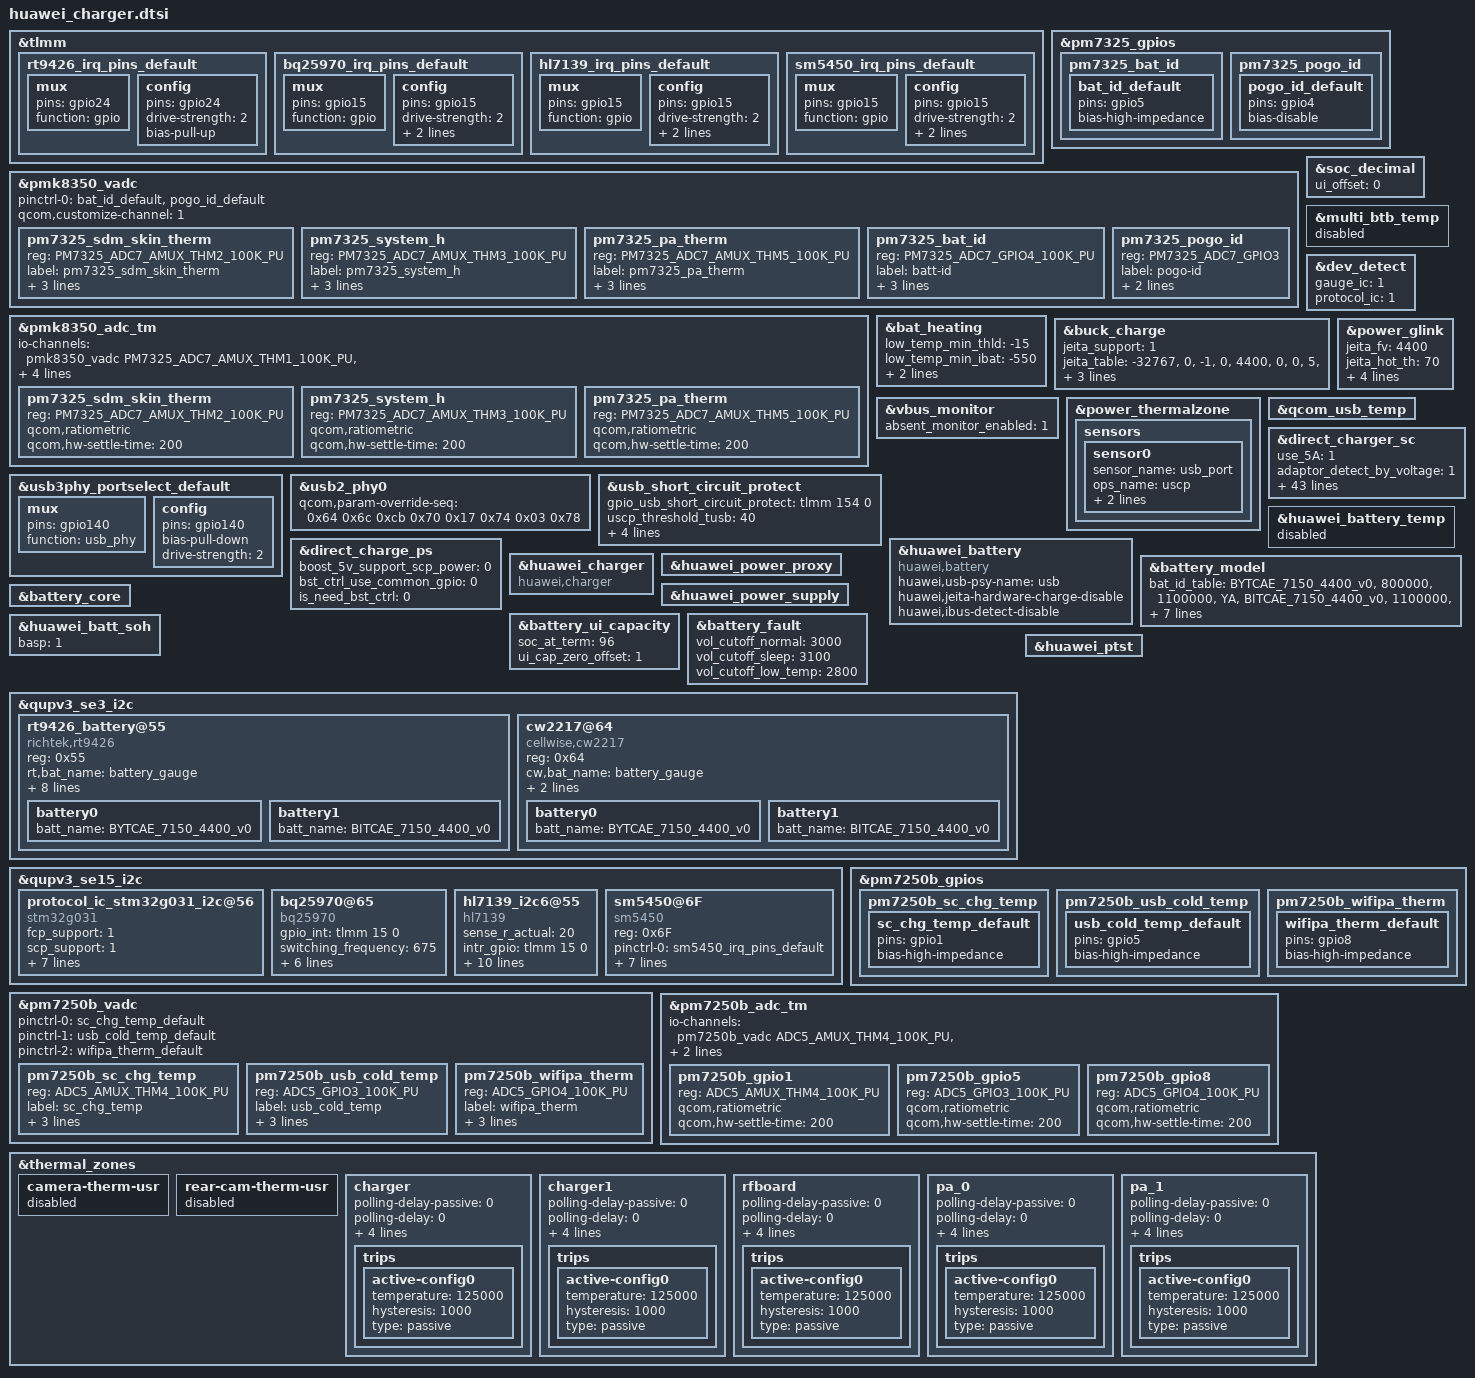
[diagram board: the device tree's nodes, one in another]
#include <dt-bindings/iio/qcom,spmi-vadc.h>

&tlmm {
	rt9426_irq_pins_default: rt9426_irq_pins_default {
		mux {
			pins = "gpio24";
			function = "gpio";
		};
		config {
			pins = "gpio24";
			drive-strength = <2>;
			bias-pull-up;
		};
	};

	bq25970_irq_pins_default: bq25970_irq_pins_default {
		mux {
			pins = "gpio15";
			function = "gpio";
		};
		config {
			pins = "gpio15";
			drive-strength = <2>;
			bias-pull-up;
			input-enable;
		};
	};

	hl7139_irq_pins_default: hl7139_irq_pins_default {
		mux {
			pins = "gpio15";
			function = "gpio";
		};
		config {
			pins = "gpio15";
			drive-strength = <2>;
			bias-pull-up;
			input-enable;
		};
	};

	sm5450_irq_pins_default: sm5450_irq_pins_default {
		mux {
			pins = "gpio15";
			function = "gpio";
		};
		config {
			pins = "gpio15";
			drive-strength = <2>;
			bias-pull-up;
			input-enable;
		};
	};
};

&pm7325_gpios {
	pm7325_bat_id {
		bat_id_default: bat_id_default {
		pins = "gpio5";
		bias-high-impedance;
		};
	};

	pm7325_pogo_id {
		pogo_id_default: pogo_id_default {
			pins = "gpio4";
			bias-disable;
		};
	};
};

&pmk8350_vadc {
	pinctrl-names = "default";
	pinctrl-0 = < &bat_id_default &pogo_id_default>;
	qcom,customize-channel = <1>;

	/delete-node/ pm7325_cam_flash_therm;
	/delete-node/ pm7325_wide_rfc_therm;

	pm7325_sdm_skin_therm {
		reg = <PM7325_ADC7_AMUX_THM2_100K_PU>;
		label = "pm7325_sdm_skin_therm";
		qcom,ratiometric;
		qcom,hw-settle-time = <200>;
		qcom,pre-scaling = <1 1>;
	};

	pm7325_system_h {
		reg = <PM7325_ADC7_AMUX_THM3_100K_PU>;
		label = "pm7325_system_h";
		qcom,ratiometric;
		qcom,hw-settle-time = <200>;
		qcom,pre-scaling = <1 1>;
	};

	pm7325_pa_therm {
		reg = <PM7325_ADC7_AMUX_THM5_100K_PU>;
		label = "pm7325_pa_therm";
		qcom,ratiometric;
		qcom,hw-settle-time = <200>;
		qcom,pre-scaling = <1 1>;
	};

	pm7325_bat_id {
		reg = < PM7325_ADC7_GPIO4_100K_PU>;
		label = "batt-id";
		qcom,ratiometric;
		qcom,hw-settle-time = <200>;
		qcom,pre-scaling = <1 1>;
	};

	pm7325_pogo_id {
		reg = <PM7325_ADC7_GPIO3>;
		label = "pogo-id";
		qcom,hw-settle-time = <200>;
		qcom,pre-scaling = <1 1>;
	};
};


&pmk8350_adc_tm {
	io-channels = <&pmk8350_vadc PM7325_ADC7_AMUX_THM1_100K_PU>,
			<&pmk8350_vadc PM7325_ADC7_AMUX_THM2_100K_PU>,
			<&pmk8350_vadc PM7325_ADC7_AMUX_THM3_100K_PU>,
			<&pmk8350_vadc PM7325_ADC7_AMUX_THM5_100K_PU>,
			<&pmk8350_vadc PMK8350_ADC7_AMUX_THM1_100K_PU>;

	/delete-node/ pm7325_cam_flash_therm;
	/delete-node/ pm7325_wide_rfc_therm;

	pm7325_sdm_skin_therm {
		reg = <PM7325_ADC7_AMUX_THM2_100K_PU>;
		qcom,ratiometric;
		qcom,hw-settle-time = <200>;
	};

	pm7325_system_h {
		reg = <PM7325_ADC7_AMUX_THM3_100K_PU>;
		qcom,ratiometric;
		qcom,hw-settle-time = <200>;
	};

	pm7325_pa_therm {
		reg = <PM7325_ADC7_AMUX_THM5_100K_PU>;
		qcom,ratiometric;
		qcom,hw-settle-time = <200>;
	};
};

&bat_heating {
	low_temp_min_thld = "-15";
	low_temp_min_ibat = "-550";
	temp_para =
		"-32767", "0", "0",
		"0", "5", "0",
		"5", "10", "400",
		"10", "20", "2500",
		"20", "45", "4500",
		"45", "32767", "0";
	status = "ok";
};

&soc_decimal {
	ui_offset = <0>;
	status = "ok";
};

&multi_btb_temp {
	status = "disabled";
};

&dev_detect {
        gauge_ic = <1>;
        protocol_ic = <1>;
        status = "ok";
};

&buck_charge {
	jeita_support = <1>;
	jeita_table =
		"-32767", "0", "-1", "0", "4400", "0",
		"0", "5", "-1", "715", "4400", "0",
		"5", "10", "-1", "2145", "4400", "3",
		"10", "45", "-1", "3000", "4400", "3",
		"45", "50", "-1", "2502", "4100", "3",
		"50", "32767", "-1", "0", "4100", "0";
	status = "ok";
};

&power_glink {
	jeita_fv = <4400>;
	jeita_hot_th = <70>;
	fcp_pd_support_icl = <1>;
	iterm = <200>;
	adsp_jeita_table = <
		0 5 3000 4400
		5 10 3000 4400
		10 65 3000 4400
		65 70 3000 4400
	>;
};

&vbus_monitor {
	status = "ok";
	absent_monitor_enabled = <1>;
};

&power_thermalzone {
	status = "ok";
	sensors{
		sensor0 {
			sensor_name = "usb_port";
			ops_name = "uscp";
			adc_channel = <0>;
			ntc_index = <5>;
		};
	};
};

&qcom_usb_temp {
	status = "ok";
};

&usb3phy_portselect_default {
	mux {
		pins = "gpio140";
		function = "usb_phy";
	};

	config {
		pins = "gpio140";
		bias-pull-down;
		drive-strength = <2>;
	};
};

&usb2_phy0 {
	status = "ok";
			qcom,param-override-seq =
				<0x64 0x6c  /* override_x0 */
				0xcb 0x70  /* override_x1 */
				0x17 0x74  /* override_x2 */
				0x03 0x78>;    /* override_x3 */
};

&usb_short_circuit_protect {
	gpio_usb_short_circuit_protect = <&tlmm 154 0>; /* GPIO_154 */
	uscp_threshold_tusb = <40>;
	open_mosfet_temp = <30>;
	close_mosfet_temp = <10>;
	open_hiz_temp = <30>;
	interval_switch_temp = <15>;
	status = "ok";
};

&direct_charge_ps {
	boost_5v_support_scp_power = <0>;
	bst_ctrl_use_common_gpio = <0>;
	is_need_bst_ctrl = <0>;
	status = "ok";
};

&direct_charger_sc {
	use_5A = <1>;
	adaptor_detect_by_voltage = <1>;
	adaptor_antifake_check_enable = <0>;
	adaptor_antifake_key_index = <2>;
	need_wired_sw_off = <0>;
	dc_volt_ratio = <2>;
	max_adaptor_vset = <10000>;
	init_adapter_vset = <8800>;
	delta_err_10v2p25a = <150>;
	vol_err_th = <500>;
	adaptor_leakage_current_th = <600>;
	high_temp_hysteresis = <1>;
	gain_curr_10v2a = <300>;
	gain_curr_10v2p25a = <500>;
	init_delt_vset = <450>;
	vstep = <20>;
	min_dc_bat_vol = <3450>;
	max_dc_bat_vol = <4380>;
	product_max_pwr = <66000>;
	max_current_for_none_standard_cable = <6000>;
	volt_para =
		"4300","5000","4900",
		"4400","5000","1200";
	volt_para1 =
		"4300","5000","4900",
		"4400","5000","1200";
	time_para =
		"1140", "6200",
		"960", "8200",
		"360", "9300";
	bat_para =
		"CAE", "10", "20", "volt_para",
		"CAE", "20", "45", "volt_para1",
		"default", "10", "20", "volt_para",
		"default", "20", "45", "volt_para1";
	vstep_para =
			"2000", "80";
	compensate_r = <0>;
	cc_cable_detect_enable = <1>;
	full_path_res_max = <500>;
	scp_work_on_charger = <1>;
	standard_cable_full_path_res_max = <500>;
	first_cc_stage_timer_in_min = <14>;
	stage_need_to_jump = "-1";
	is_show_ico_first = <1>;
	is_send_cable_type = <0>;
	support_multi_ic = <1>;
	rt_test_para =
		/* first:sc second:mainsc third:auxsc */
		"500", "105",
		"500", "105",
		"500", "105";
	temp_para =
		"-32767", "10", "0",
		"10", "45", "13000",
		"45", "32767", "0";
	resist_para =
		"0", "300", "6000",
		"300", "500", "5000";
	std_resist_para =
		"0", "300", "13000",
		"300", "500", "5000";
	10v2p25a_cur_para =
		"-32767", "5500",  "2000",
		"5500",   "9000",  "2500",
		"9000",   "10000", "2250",
		"10000",  "10500", "2000",
		"10500",  "32767", "1500";
	status = "ok";
};

&huawei_battery_temp {
	status = "disabled";
};

&huawei_battery {
	compatible = "huawei,battery";
	status = "ok";
	huawei,usb-psy-name = "usb";
	huawei,jeita-hardware-charge-disable;
	huawei,ibus-detect-disable;
};

&huawei_charger {
	compatible = "huawei,charger";
	status = "ok";
};

&battery_model {
	bat_id_table =
		"BYTCAE_7150_4400_v0", "800000", "1100000", "YA",
		"BITCAE_7150_4400_v0", "1100000", "1350000", "CA";
	design_fcc = <7150>;

	support_iio = <1>;
	io-channels = <&pmk8350_vadc PM7325_ADC7_GPIO4_100K_PU>;
	io-channel-names = "batt-id";

	id_adc_channel = <0>; /* useless but necessary for Qcom, set 0 as default */
	technology = <2>;
	status = "ok";
};

&huawei_power_proxy {
	status = "ok";
};

&huawei_power_supply {
	 status = "ok";
};

&battery_core {
	status = "ok";
};

&battery_ui_capacity {
	soc_at_term = <96>;
	ui_cap_zero_offset = <1>;
	status = "ok";
};

&battery_fault {
	vol_cutoff_normal = <3000>;
	vol_cutoff_sleep = <3100>;
	vol_cutoff_low_temp = <2800>;
	status = "ok";
};

&huawei_batt_soh {
	basp = <1>;
	status = "ok";
};

&qupv3_se3_i2c {
	#address-cells = <1>;
	#size-cells = <0>;
	status = "ok";
	rt9426_battery@55{
		reg = <0x55>;
		compatible = "richtek,rt9426";
		rt,bat_name = "battery_gauge";
		pinctrl-names = "default";
		pinctrl-0 = <&rt9426_irq_pins_default>;
		rt9426,gpio-intb = <&tlmm 24 0x0>;
		need_reset_version = <9>;
		rt_config_ver = <11>;
		ntc_compensation_is = <1>;
		ntc_temp_compensation_para =
			"17000", "170",
			"15000", "150",
			"13000", "130",
			"11000", "110",
			"9000", "80",
			"7000", "50",
			"6000", "40",
			"5000", "30",
			"3000", "20",
			"2000", "10";
		status = "ok";
		battery0{
			batt_name = "BYTCAE_7150_4400_v0";
			#include "../../../huawei_charger/rt9426_BYTCAE_4V4_7150mAh_BACH4.dtsi"
		};
		battery1{
			batt_name = "BITCAE_7150_4400_v0";
			#include "../../../huawei_charger/rt9426_BITCAE_4V4_7150mAh_BACH4.dtsi"
		};
	};

	cw2217@64 {
		compatible = "cellwise,cw2217";
		reg = <0x64>;
		cw,bat_name = "battery_gauge";
		ground_loop_comp_en = <1>;
		ground_loop_comp_rcomp = <125>;
		status = "ok";
		battery0{
			batt_name = "BYTCAE_7150_4400_v0";
			#include "../../../huawei_charger/cw2217_2mohm_BYTCAE_7150mAh_4V4_BACH4.dtsi"
		};
		battery1{
			batt_name = "BITCAE_7150_4400_v0";
			#include "../../../huawei_charger/cw2217_2mohm_BITCAE_7150mAh_4V4_BACH4.dtsi"
		};
	};
};

&qupv3_se15_i2c {
	#address-cells = <1>;
	#size-cells = <0>;
	status = "ok";

	protocol_ic_stm32g031_i2c@56 {
		compatible = "stm32g031";
		fcp_support = <1>;
		scp_support = <1>;
		ufcs_support = <1>;
		wait_time = <20>;
		hw_config = <0x20>;
		gpio_enable = <&tlmm 68 0>;
		gpio_reset = <&tlmm 33 0>;
		gpio_int = <&tlmm 16 0>;
		reg = <0x56>;
		status = "ok";
	};

	bq25970@65 {
		compatible = "bq25970";
		gpio_int = <&tlmm 15 0>;
		switching_frequency = <675>;
		reg = <0x65>;
		pinctrl-names = "default";
		pinctrl-0 = <&bq25970_irq_pins_default>;
		ic_role = <0>;
		sense_r_actual = <20>;
		resume_need_wait_i2c = <1>;
		reset_ac_ovp = <1>;
		status = "ok";
	};

	hl7139_i2c6@55 {
		compatible = "hl7139";
		pinctrl-names = "default";
		sense_r_actual = <20>;
		intr_gpio = <&tlmm 15 0>;
		pinctrl-0 = <&hl7139_irq_pins_default>;
		fcp_support = <1>;
		scp_support = <1>;
		switching_frequency = <675>;
		reg = <0x55>;
		vbat_ovp_para = <5000>;
		ibat_ocp_para = <6000>;
		vin_ovp_para = <11500>;
		iin_ocp_para = <3750>;
		sc_ibus_ocp = <3750>;
		status = "ok";
	};

	sm5450@6F {
		compatible = "sm5450";
		reg = <0x6F>;
		pinctrl-names = "default";
		pinctrl-0 = <&sm5450_irq_pins_default>;
		intr_gpio_num = <15>; /* direct defined GPIO num */
		intr_gpio = <&tlmm 15 0>;
		fcp_support = <1>;
		scp_support = <1>;
		sense_r_actual = <20>;
		close_regulation = <1>;
		sc_ibus_ocp = <5700>;
		status = "ok";
	};
};

&huawei_ptst {
	status = "ok";
};


&pm7250b_gpios {
	pm7250b_sc_chg_temp {
		sc_chg_temp_default: sc_chg_temp_default {
			pins = "gpio1";
			bias-high-impedance;
		};
	};

	pm7250b_usb_cold_temp {
		usb_cold_temp_default: usb_cold_temp_default {
			pins = "gpio5";
			bias-high-impedance;
		};
	};

	pm7250b_wifipa_therm {
		wifipa_therm_default: wifipa_therm_default {
			pins = "gpio8";
			bias-high-impedance;
		};
	};

};

&pm7250b_vadc {
	#address-cells = <1>;
	#size-cells = <0>;
	pinctrl-names = "default", "default", "default";
	pinctrl-0 = <&sc_chg_temp_default>;
	pinctrl-1 = <&usb_cold_temp_default>;
	pinctrl-2 = <&wifipa_therm_default>;

	pm7250b_sc_chg_temp {
		reg = <ADC5_AMUX_THM4_100K_PU>;
		label = "sc_chg_temp";
		qcom,ratiometric;
		qcom,hw-settle-time = <200>;
		qcom,pre-scaling = <1 1>;
	};

	pm7250b_usb_cold_temp {
		reg = <ADC5_GPIO3_100K_PU>;
		label = "usb_cold_temp";
		qcom,ratiometric;
		qcom,hw-settle-time = <200>;
		qcom,pre-scaling = <1 1>;
	};

	pm7250b_wifipa_therm {
		reg = <ADC5_GPIO4_100K_PU>;
		label = "wifipa_therm";
		qcom,ratiometric;
		qcom,hw-settle-time = <200>;
		qcom,pre-scaling = <1 1>;
	};
};

&pm7250b_adc_tm {
	#address-cells = <1>;
	#size-cells = <0>;
	io-channels = <&pm7250b_vadc ADC5_AMUX_THM4_100K_PU>,
			<&pm7250b_vadc ADC5_GPIO3_100K_PU>,
			<&pm7250b_vadc ADC5_GPIO4_100K_PU>;

	pm7250b_gpio1 {
		reg = <ADC5_AMUX_THM4_100K_PU>;
		qcom,ratiometric;
		qcom,hw-settle-time = <200>;
	};

	pm7250b_gpio5 {
		reg = <ADC5_GPIO3_100K_PU>;
		qcom,ratiometric;
		qcom,hw-settle-time = <200>;
	};

	pm7250b_gpio8 {
		reg = <ADC5_GPIO4_100K_PU>;
		qcom,ratiometric;
		qcom,hw-settle-time = <200>;
	};
};

&thermal_zones {
	camera-therm-usr {
		status = "disabled";
	};
	rear-cam-therm-usr {
		status = "disabled";
	};
	charger {
		polling-delay-passive = <0>;
		polling-delay = <0>;
		thermal-governor = "user_space";
		thermal-sensors = <&pm7250b_adc_tm ADC5_AMUX_THM4_100K_PU>;
		wake-capable-sensor;
		trips {
			active-config0 {
				temperature = <125000>;
				hysteresis = <1000>;
				type = "passive";
			};
		};
	};

	charger1 {
		polling-delay-passive = <0>;
		polling-delay = <0>;
		thermal-governor = "user_space";
		thermal-sensors = <&pmk8350_adc_tm PM7325_ADC7_AMUX_THM2_100K_PU>;
		wake-capable-sensor;
		trips {
			active-config0 {
				temperature = <125000>;
				hysteresis = <1000>;
				type = "passive";
			};
		};
	};

	rfboard {
		polling-delay-passive = <0>;
		polling-delay = <0>;
		thermal-governor = "user_space";
		thermal-sensors = <&pm7250b_adc_tm ADC5_GPIO3_100K_PU>;
		wake-capable-sensor;
		trips {
			active-config0 {
				temperature = <125000>;
				hysteresis = <1000>;
				type = "passive";
			};
		};
	};

	pa_0 {
		polling-delay-passive = <0>;
		polling-delay = <0>;
		thermal-governor = "user_space";
		thermal-sensors = <&pmk8350_adc_tm PM7325_ADC7_AMUX_THM5_100K_PU>;
		wake-capable-sensor;
		trips {
			active-config0 {
				temperature = <125000>;
				hysteresis = <1000>;
				type = "passive";
			};
		};
	};

	pa_1 {
		polling-delay-passive = <0>;
		polling-delay = <0>;
		thermal-governor = "user_space";
		thermal-sensors = <&pm7250b_adc_tm ADC5_GPIO4_100K_PU>;
		wake-capable-sensor;
		trips {
			active-config0 {
				temperature = <125000>;
				hysteresis = <1000>;
				type = "passive";
			};
		};
	};
};
